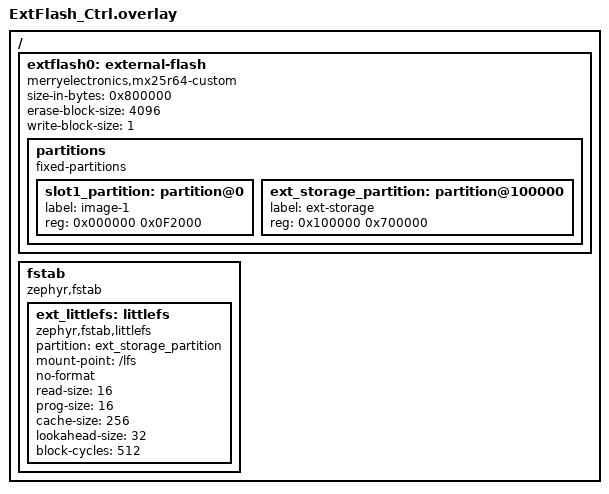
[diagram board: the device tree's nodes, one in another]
/ {
    extflash0: external-flash {
        compatible = "merryelectronics,mx25r64-custom";
        status = "okay";

        /* Devicetree size is expressed in bits: 64 Mbit = 8 MiB. */
        size-in-bytes = <0x800000>;
        erase-block-size = <4096>;
        write-block-size = <1>;

        partitions {

            compatible = "fixed-partitions";
            #address-cells = <1>;
            #size-cells = <1>;

            /*
             * Swap-using-offset reserves the first 8 KiB sector and stores
             * the update image at offset 0x2000.  The secondary slot is one
             * 8 KiB sector larger than the 960 KiB primary slot.
             */
            slot1_partition: partition@0 {
                label = "image-1";
                reg = <0x000000 0x0F2000>;
            };

            /* 0x0F2000-0x0FFFFF is intentionally left unused. */
            ext_storage_partition: partition@100000 {
                label = "ext-storage";
                reg = <0x100000 0x700000>;
            };
        };
    };
};

/{
    fstab {
        compatible = "zephyr,fstab";

        ext_littlefs: littlefs {

            compatible = "zephyr,fstab,littlefs";
            status = "okay";
            partition = <&ext_storage_partition>;
            mount-point = "/lfs";

            no-format;

            read-size = <16>;
            prog-size = <16>;
            cache-size = <256>;
            lookahead-size = <32>;
            block-cycles = <512>;

        };        
    };
};
